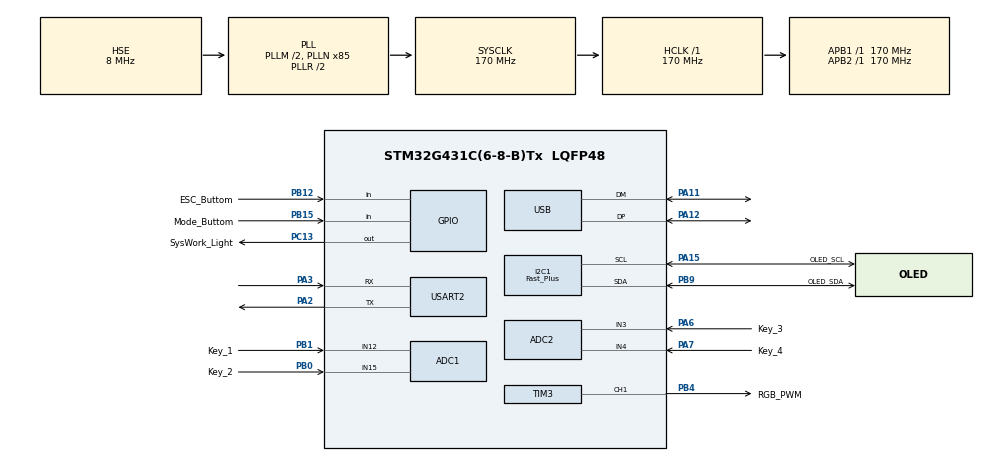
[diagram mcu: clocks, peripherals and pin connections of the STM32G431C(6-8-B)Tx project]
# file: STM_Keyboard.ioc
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ADC1.Channel-3\#ChannelRegularConversion=ADC_CHANNEL_12
ADC1.Channel-4\#ChannelRegularConversion=ADC_CHANNEL_15
ADC1.ContinuousConvMode=ENABLE
ADC1.DMAContinuousRequests=ENABLE
ADC1.NbrOfConversion=2
ADC1.NbrOfConversionFlag=1
ADC1.OffsetNumber-3\#ChannelRegularConversion=ADC_OFFSET_NONE
ADC1.OffsetNumber-4\#ChannelRegularConversion=ADC_OFFSET_NONE
ADC1.Rank-3\#ChannelRegularConversion=1
ADC1.Rank-4\#ChannelRegularConversion=2
ADC1.SamplingTime-3\#ChannelRegularConversion=ADC_SAMPLETIME_2CYCLES_5
ADC1.SamplingTime-4\#ChannelRegularConversion=ADC_SAMPLETIME_2CYCLES_5
ADC1.master=1
ADC2.Channel-4\#ChannelRegularConversion=ADC_CHANNEL_3
ADC2.Channel-5\#ChannelRegularConversion=ADC_CHANNEL_4
ADC2.ContinuousConvMode=ENABLE
ADC2.DMAContinuousRequests=ENABLE
ADC2.NbrOfConversion=2
ADC2.NbrOfConversionFlag=1
ADC2.OffsetNumber-4\#ChannelRegularConversion=ADC_OFFSET_NONE
ADC2.OffsetNumber-5\#ChannelRegularConversion=ADC_OFFSET_NONE
ADC2.Rank-4\#ChannelRegularConversion=1
ADC2.Rank-5\#ChannelRegularConversion=2
ADC2.SamplingTime-4\#ChannelRegularConversion=ADC_SAMPLETIME_2CYCLES_5
ADC2.SamplingTime-5\#ChannelRegularConversion=ADC_SAMPLETIME_2CYCLES_5
Dma.ADC1.0.Direction=DMA_PERIPH_TO_MEMORY
Dma.ADC1.0.EventEnable=DISABLE
Dma.ADC1.0.Instance=DMA1_Channel1
Dma.ADC1.0.MemDataAlignment=DMA_MDATAALIGN_HALFWORD
Dma.ADC1.0.MemInc=DMA_MINC_ENABLE
Dma.ADC1.0.Mode=DMA_CIRCULAR
Dma.ADC1.0.PeriphDataAlignment=DMA_PDATAALIGN_HALFWORD
Dma.ADC1.0.PeriphInc=DMA_PINC_DISABLE
Dma.ADC1.0.Polarity=HAL_DMAMUX_REQ_GEN_RISING
Dma.ADC1.0.Priority=DMA_PRIORITY_MEDIUM
Dma.ADC1.0.RequestNumber=1
Dma.ADC1.0.SignalID=NONE
Dma.ADC1.0.SyncEnable=DISABLE
Dma.ADC1.0.SyncPolarity=HAL_DMAMUX_SYNC_NO_EVENT
Dma.ADC1.0.SyncRequestNumber=1
Dma.ADC1.0.SyncSignalID=NONE
Dma.ADC2.1.Direction=DMA_PERIPH_TO_MEMORY
Dma.ADC2.1.EventEnable=DISABLE
Dma.ADC2.1.Instance=DMA1_Channel2
Dma.ADC2.1.MemDataAlignment=DMA_MDATAALIGN_HALFWORD
Dma.ADC2.1.MemInc=DMA_MINC_ENABLE
Dma.ADC2.1.Mode=DMA_CIRCULAR
Dma.ADC2.1.PeriphDataAlignment=DMA_PDATAALIGN_HALFWORD
Dma.ADC2.1.PeriphInc=DMA_PINC_DISABLE
Dma.ADC2.1.Polarity=HAL_DMAMUX_REQ_GEN_RISING
Dma.ADC2.1.Priority=DMA_PRIORITY_MEDIUM
Dma.ADC2.1.RequestNumber=1
Dma.ADC2.1.SignalID=NONE
Dma.ADC2.1.SyncEnable=DISABLE
Dma.ADC2.1.SyncPolarity=HAL_DMAMUX_SYNC_NO_EVENT
Dma.ADC2.1.SyncRequestNumber=1
Dma.ADC2.1.SyncSignalID=NONE
Dma.Request0=ADC1
Dma.Request1=ADC2
Dma.Request2=TIM3_CH1
Dma.TIM3_CH1.2.Direction=DMA_MEMORY_TO_PERIPH
Dma.TIM3_CH1.2.EventEnable=DISABLE
Dma.TIM3_CH1.2.Instance=DMA1_Channel3
Dma.TIM3_CH1.2.MemDataAlignment=DMA_MDATAALIGN_HALFWORD
Dma.TIM3_CH1.2.MemInc=DMA_MINC_ENABLE
Dma.TIM3_CH1.2.Mode=DMA_NORMAL
Dma.TIM3_CH1.2.PeriphDataAlignment=DMA_PDATAALIGN_HALFWORD
Dma.TIM3_CH1.2.PeriphInc=DMA_PINC_DISABLE
Dma.TIM3_CH1.2.Polarity=HAL_DMAMUX_REQ_GEN_RISING
Dma.TIM3_CH1.2.Priority=DMA_PRIORITY_LOW
Dma.TIM3_CH1.2.RequestNumber=1
Dma.TIM3_CH1.2.SignalID=NONE
Dma.TIM3_CH1.2.SyncEnable=DISABLE
Dma.TIM3_CH1.2.SyncPolarity=HAL_DMAMUX_SYNC_NO_EVENT
Dma.TIM3_CH1.2.SyncRequestNumber=1
Dma.TIM3_CH1.2.SyncSignalID=NONE
I2C1.I2C_Speed_Mode=I2C_Fast_Plus
I2C1.Timing=0x4052060F
Mcu.Family=STM32G4
Mcu.Name=STM32G431C(6-8-B)Tx
Mcu.Package=LQFP48
NVIC.DMA1_Channel1_IRQn=true\:0\:0\:false\:false\:true\:false\:true\:true
NVIC.DMA1_Channel2_IRQn=true\:0\:0\:false\:false\:true\:false\:true\:true
NVIC.DMA1_Channel3_IRQn=true\:0\:0\:false\:false\:true\:false\:true\:true
NVIC.PriorityGroup=NVIC_PRIORITYGROUP_4
NVIC.TIM6_DAC_IRQn=true\:0\:0\:true\:false\:true\:true\:true\:true
NVIC.USB_LP_IRQn=true\:0\:0\:false\:false\:true\:false\:true\:true
PA11.Mode=Device
PA11.Signal=USB_DM
PA12.Mode=Device
PA12.Signal=USB_DP
PA13.Mode=Serial_Wire
PA13.Signal=SYS_JTMS-SWDIO
PA14.Mode=Serial_Wire
PA14.Signal=SYS_JTCK-SWCLK
PA15.GPIO_Label=OLED_SCL
PA15.Mode=I2C
PA15.Signal=I2C1_SCL
PA2.Mode=Asynchronous
PA2.Signal=USART2_TX
PA3.Mode=Asynchronous
PA3.Signal=USART2_RX
PA6.GPIO_Label=Key_3
PA6.Mode=IN3-Single-Ended
PA6.Signal=ADC2_IN3
PA7.GPIO_Label=Key_4
PA7.Mode=IN4-Single-Ended
PA7.Signal=ADC2_IN4
PB0.GPIO_Label=Key_2
PB0.Mode=IN15-Single-Ended
PB0.Signal=ADC1_IN15
PB1.GPIO_Label=Key_1
PB1.Mode=IN12-Single-Ended
PB1.Signal=ADC1_IN12
PB12.GPIO_Label=ESC_Buttom
PB12.GPIO_PuPd=GPIO_NOPULL
PB12.Signal=GPIO_Input
PB15.GPIO_Label=Mode_Buttom
PB15.GPIO_PuPd=GPIO_NOPULL
PB15.Signal=GPIO_Input
PB4.GPIO_Label=RGB_PWM
PB4.GPIO_ModeDefaultPP=GPIO_MODE_AF_PP
PB4.GPIO_Speed=GPIO_SPEED_FREQ_HIGH
PB4.Signal=S_TIM3_CH1
PB9.GPIO_Label=OLED_SDA
PB9.Mode=I2C
PB9.Signal=I2C1_SDA
PC13.GPIO_Label=SysWork_Light
PC13.GPIO_ModeDefaultOutputPP=GPIO_MODE_OUTPUT_PP
PC13.GPIO_PuPd=GPIO_PULLDOWN
PC13.Signal=GPIO_Output
PF0-OSC_IN.Mode=HSE-External-Oscillator
PF0-OSC_IN.Signal=RCC_OSC_IN
PF1-OSC_OUT.Mode=HSE-External-Oscillator
PF1-OSC_OUT.Signal=RCC_OSC_OUT
ProjectManager.HeapSize=0x200
ProjectManager.StackSize=0x400
ProjectManager.TargetToolchain=STM32CubeIDE
RCC.ADC12Freq_Value=170000000
RCC.AHBFreq_Value=170000000
RCC.APB1Freq_Value=170000000
RCC.APB1TimFreq_Value=170000000
RCC.APB2Freq_Value=170000000
RCC.APB2TimFreq_Value=170000000
RCC.CK48CLockSelection=RCC_USBCLKSOURCE_HSI48
RCC.CortexFreq_Value=170000000
RCC.EXTERNAL_CLOCK_VALUE=12288000
RCC.HCLKFreq_Value=170000000
RCC.HSE_VALUE=8000000
RCC.HSI48_VALUE=48000000
RCC.HSI_VALUE=16000000
RCC.LSE_VALUE=32768
RCC.PLLM=RCC_PLLM_DIV2
RCC.PLLN=85
RCC.PLLSourceVirtual=RCC_PLLSOURCE_HSE
RCC.SYSCLKFreq_VALUE=170000000
RCC.SYSCLKSource=RCC_SYSCLKSOURCE_PLLCLK
RCC.USBFreq_Value=48000000
RCC.VCOOutputFreq_Value=340000000
SH.S_TIM3_CH1.0=TIM3_CH1,PWM Generation1 CH1
TIM3.Channel-PWM\ Generation1\ CH1=TIM_CHANNEL_1
TIM3.PeriodNoDither=212
TIM3.Prescaler=0
TIM6.PeriodNoDither=10000-1
TIM6.Prescaler=170-1
USART2.VirtualMode-Asynchronous=VM_ASYNC
USB_DEVICE.CLASS_NAME_FS=HID
USB_DEVICE.HID_FS_BINTERVAL=0x1
USB_DEVICE.USBD_LPM_ENABLED=0
USB_DEVICE.VirtualMode=Hid
USB_DEVICE.VirtualModeFS=Hid_FS
VP_CRC_VS_CRC.Mode=CRC_Activate
VP_SYS_VS_DBSignals.Mode=DisableDeadBatterySignals
VP_SYS_V_VREFBUF.Mode=ExternalMode
VP_TIM3_VS_ClockSourceINT.Mode=Internal
VP_TIM6_VS_ClockSourceINT.Mode=Enable_Timer
VP_USB_DEVICE_VS_USB_DEVICE_HID_FS.Mode=HID_FS
board=custom

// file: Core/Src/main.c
/* USER CODE BEGIN Header */
/**
  ******************************************************************************
  * @file           : main.c
  * @brief          : Main program body
  ******************************************************************************
  * @attention
  *
  * Copyright (c) 2025 STMicroelectronics.
  * All rights reserved.
  *
  * This software is licensed under terms that can be found in the LICENSE file
  * in the root directory of this software component.
  * If no LICENSE file comes with this software, it is provided AS-IS.
  *
  ******************************************************************************
  */
/* USER CODE END Header */
#include "main.h"
#include "adc.h"
#include "crc.h"
#include "dma.h"
#include "i2c.h"
#include "tim.h"
#include "usart.h"
#include "usb_device.h"
#include "gpio.h"

/* USER CODE BEGIN Includes */
#include "oled.h"
#include "oled_optimize.h"
#include "rgb_controller.h"
#include "adc_controller.h"
#include "keyboard_controller.h"
#include "oled_driver.h"
#include <math.h>
/* USER CODE END Includes */

void SystemClock_Config(void);

int main(void)
{

  /* MCU Configuration--------------------------------------------------------*/

  /* Reset of all peripherals, Initializes the Flash interface and the Systick. */
  HAL_Init();

  /* Configure the system clock */
  SystemClock_Config();

  /* Initialize all configured peripherals */
  MX_GPIO_Init();
  MX_DMA_Init();
  MX_ADC2_Init();
  MX_I2C1_Init();
  MX_USB_Device_Init();
  MX_ADC1_Init();
  MX_TIM3_Init();
  MX_USART2_UART_Init();
  MX_CRC_Init();
  MX_TIM6_Init();
  /* USER CODE BEGIN 2 */
  Keyboard_Init();
  HAL_Delay(100);
  /* USER CODE END 2 */

  /* Infinite loop */
  /* USER CODE BEGIN WHILE */
  while (1)
  {
    RGB_Loop();

    /* USER CODE END WHILE */

  }
}

void SystemClock_Config(void)
{
  RCC_OscInitTypeDef RCC_OscInitStruct = {0};
  RCC_ClkInitTypeDef RCC_ClkInitStruct = {0};

  /** Configure the main internal regulator output voltage
  */
  HAL_PWREx_ControlVoltageScaling(PWR_REGULATOR_VOLTAGE_SCALE1_BOOST);

  /** Initializes the RCC Oscillators according to the specified parameters
  * in the RCC_OscInitTypeDef structure.
  */
  RCC_OscInitStruct.OscillatorType = RCC_OSCILLATORTYPE_HSI48|RCC_OSCILLATORTYPE_HSE;
  RCC_OscInitStruct.HSEState = RCC_HSE_ON;
  RCC_OscInitStruct.HSI48State = RCC_HSI48_ON;
  RCC_OscInitStruct.PLL.PLLState = RCC_PLL_ON;
  RCC_OscInitStruct.PLL.PLLSource = RCC_PLLSOURCE_HSE;
  RCC_OscInitStruct.PLL.PLLM = RCC_PLLM_DIV2;
  RCC_OscInitStruct.PLL.PLLN = 85;
  RCC_OscInitStruct.PLL.PLLP = RCC_PLLP_DIV2;
  RCC_OscInitStruct.PLL.PLLQ = RCC_PLLQ_DIV2;
  RCC_OscInitStruct.PLL.PLLR = RCC_PLLR_DIV2;
  if (HAL_RCC_OscConfig(&RCC_OscInitStruct) != HAL_OK)
  {
    Error_Handler();
  }

  /** Initializes the CPU, AHB and APB buses clocks
  */
  RCC_ClkInitStruct.ClockType = RCC_CLOCKTYPE_HCLK|RCC_CLOCKTYPE_SYSCLK
                              |RCC_CLOCKTYPE_PCLK1|RCC_CLOCKTYPE_PCLK2;
  RCC_ClkInitStruct.SYSCLKSource = RCC_SYSCLKSOURCE_PLLCLK;
  RCC_ClkInitStruct.AHBCLKDivider = RCC_SYSCLK_DIV1;
  RCC_ClkInitStruct.APB1CLKDivider = RCC_HCLK_DIV1;
  RCC_ClkInitStruct.APB2CLKDivider = RCC_HCLK_DIV1;

  if (HAL_RCC_ClockConfig(&RCC_ClkInitStruct, FLASH_LATENCY_4) != HAL_OK)
  {
    Error_Handler();
  }
}

void Error_Handler(void)
{
  __disable_irq();
  while (1)
  {
  }
}
